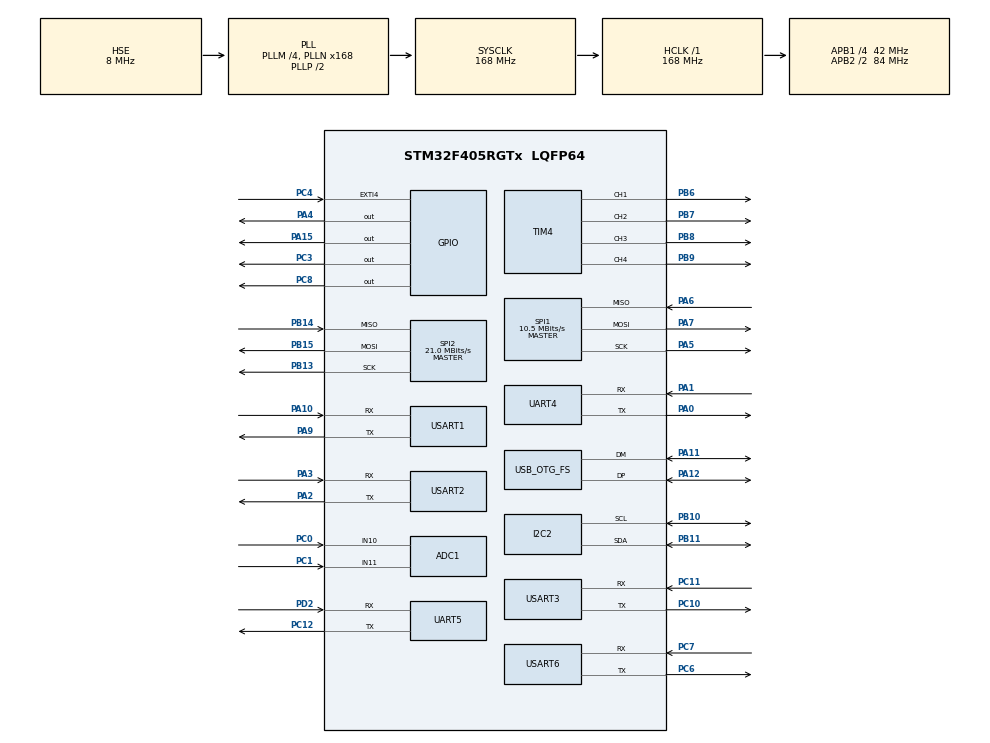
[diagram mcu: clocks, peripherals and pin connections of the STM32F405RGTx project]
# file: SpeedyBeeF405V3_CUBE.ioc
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ADC1.Channel-0\#ChannelRegularConversion=ADC_CHANNEL_10
ADC1.Channel-3\#ChannelRegularConversion=ADC_CHANNEL_11
ADC1.Channel-4\#ChannelRegularConversion=ADC_CHANNEL_TEMPSENSOR
ADC1.Channel-5\#ChannelRegularConversion=ADC_CHANNEL_VREFINT
ADC1.Channel-6\#ChannelRegularConversion=ADC_CHANNEL_VBAT
ADC1.ClockPrescaler=ADC_CLOCK_SYNC_PCLK_DIV8
ADC1.ContinuousConvMode=ENABLE
ADC1.DMAContinuousRequests=ENABLE
ADC1.ExternalTrigConv=ADC_SOFTWARE_START
ADC1.ExternalTrigConvEdge=ADC_EXTERNALTRIGCONVEDGE_NONE
ADC1.InjNumberOfConversion=0
ADC1.NbrOfConversion=5
ADC1.NbrOfConversionFlag=1
ADC1.Rank-0\#ChannelRegularConversion=1
ADC1.Rank-3\#ChannelRegularConversion=2
ADC1.Rank-4\#ChannelRegularConversion=3
ADC1.Rank-5\#ChannelRegularConversion=4
ADC1.Rank-6\#ChannelRegularConversion=5
ADC1.SamplingTime-0\#ChannelRegularConversion=ADC_SAMPLETIME_480CYCLES
ADC1.SamplingTime-3\#ChannelRegularConversion=ADC_SAMPLETIME_480CYCLES
ADC1.SamplingTime-4\#ChannelRegularConversion=ADC_SAMPLETIME_480CYCLES
ADC1.SamplingTime-5\#ChannelRegularConversion=ADC_SAMPLETIME_480CYCLES
ADC1.SamplingTime-6\#ChannelRegularConversion=ADC_SAMPLETIME_480CYCLES
ADC1.ScanConvMode=ENABLE
ADC1.master=1
Dma.ADC1.10.Direction=DMA_PERIPH_TO_MEMORY
Dma.ADC1.10.FIFOMode=DMA_FIFOMODE_DISABLE
Dma.ADC1.10.Instance=DMA2_Stream0
Dma.ADC1.10.MemDataAlignment=DMA_MDATAALIGN_HALFWORD
Dma.ADC1.10.MemInc=DMA_MINC_ENABLE
Dma.ADC1.10.Mode=DMA_CIRCULAR
Dma.ADC1.10.PeriphDataAlignment=DMA_PDATAALIGN_HALFWORD
Dma.ADC1.10.PeriphInc=DMA_PINC_DISABLE
Dma.ADC1.10.Priority=DMA_PRIORITY_HIGH
Dma.Request0=SPI2_TX
Dma.Request1=USART2_RX
Dma.Request10=ADC1
Dma.Request2=SPI1_RX
Dma.Request3=SPI1_TX
Dma.Request4=SPI2_RX
Dma.Request5=USART6_RX
Dma.Request6=USART3_RX
Dma.Request7=UART4_RX
Dma.Request8=UART5_RX
Dma.Request9=USART1_RX
Dma.SPI1_RX.2.Direction=DMA_PERIPH_TO_MEMORY
Dma.SPI1_RX.2.FIFOMode=DMA_FIFOMODE_DISABLE
Dma.SPI1_RX.2.Instance=DMA2_Stream2
Dma.SPI1_RX.2.MemDataAlignment=DMA_MDATAALIGN_BYTE
Dma.SPI1_RX.2.MemInc=DMA_MINC_ENABLE
Dma.SPI1_RX.2.Mode=DMA_NORMAL
Dma.SPI1_RX.2.PeriphDataAlignment=DMA_PDATAALIGN_BYTE
Dma.SPI1_RX.2.PeriphInc=DMA_PINC_DISABLE
Dma.SPI1_RX.2.Priority=DMA_PRIORITY_LOW
Dma.SPI1_TX.3.Direction=DMA_MEMORY_TO_PERIPH
Dma.SPI1_TX.3.FIFOMode=DMA_FIFOMODE_DISABLE
Dma.SPI1_TX.3.Instance=DMA2_Stream3
Dma.SPI1_TX.3.MemDataAlignment=DMA_MDATAALIGN_BYTE
Dma.SPI1_TX.3.MemInc=DMA_MINC_ENABLE
Dma.SPI1_TX.3.Mode=DMA_NORMAL
Dma.SPI1_TX.3.PeriphDataAlignment=DMA_PDATAALIGN_BYTE
Dma.SPI1_TX.3.PeriphInc=DMA_PINC_DISABLE
Dma.SPI1_TX.3.Priority=DMA_PRIORITY_LOW
Dma.SPI2_RX.4.Direction=DMA_PERIPH_TO_MEMORY
Dma.SPI2_RX.4.FIFOMode=DMA_FIFOMODE_DISABLE
Dma.SPI2_RX.4.Instance=DMA1_Stream3
Dma.SPI2_RX.4.MemDataAlignment=DMA_MDATAALIGN_BYTE
Dma.SPI2_RX.4.MemInc=DMA_MINC_ENABLE
Dma.SPI2_RX.4.Mode=DMA_NORMAL
Dma.SPI2_RX.4.PeriphDataAlignment=DMA_PDATAALIGN_BYTE
Dma.SPI2_RX.4.PeriphInc=DMA_PINC_DISABLE
Dma.SPI2_RX.4.Priority=DMA_PRIORITY_LOW
Dma.SPI2_TX.0.Direction=DMA_MEMORY_TO_PERIPH
Dma.SPI2_TX.0.FIFOMode=DMA_FIFOMODE_DISABLE
Dma.SPI2_TX.0.Instance=DMA1_Stream4
Dma.SPI2_TX.0.MemDataAlignment=DMA_MDATAALIGN_BYTE
Dma.SPI2_TX.0.MemInc=DMA_MINC_ENABLE
Dma.SPI2_TX.0.Mode=DMA_NORMAL
Dma.SPI2_TX.0.PeriphDataAlignment=DMA_PDATAALIGN_BYTE
Dma.SPI2_TX.0.PeriphInc=DMA_PINC_DISABLE
Dma.SPI2_TX.0.Priority=DMA_PRIORITY_LOW
Dma.UART4_RX.7.Direction=DMA_PERIPH_TO_MEMORY
Dma.UART4_RX.7.FIFOMode=DMA_FIFOMODE_DISABLE
Dma.UART4_RX.7.Instance=DMA1_Stream2
Dma.UART4_RX.7.MemDataAlignment=DMA_MDATAALIGN_BYTE
Dma.UART4_RX.7.MemInc=DMA_MINC_ENABLE
Dma.UART4_RX.7.Mode=DMA_CIRCULAR
Dma.UART4_RX.7.PeriphDataAlignment=DMA_PDATAALIGN_BYTE
Dma.UART4_RX.7.PeriphInc=DMA_PINC_DISABLE
Dma.UART4_RX.7.Priority=DMA_PRIORITY_LOW
Dma.UART5_RX.8.Direction=DMA_PERIPH_TO_MEMORY
Dma.UART5_RX.8.FIFOMode=DMA_FIFOMODE_DISABLE
Dma.UART5_RX.8.Instance=DMA1_Stream0
Dma.UART5_RX.8.MemDataAlignment=DMA_MDATAALIGN_BYTE
Dma.UART5_RX.8.MemInc=DMA_MINC_ENABLE
Dma.UART5_RX.8.Mode=DMA_CIRCULAR
Dma.UART5_RX.8.PeriphDataAlignment=DMA_PDATAALIGN_BYTE
Dma.UART5_RX.8.PeriphInc=DMA_PINC_DISABLE
Dma.UART5_RX.8.Priority=DMA_PRIORITY_LOW
Dma.USART1_RX.9.Direction=DMA_PERIPH_TO_MEMORY
Dma.USART1_RX.9.FIFOMode=DMA_FIFOMODE_DISABLE
Dma.USART1_RX.9.Instance=DMA2_Stream5
Dma.USART1_RX.9.MemDataAlignment=DMA_MDATAALIGN_BYTE
Dma.USART1_RX.9.MemInc=DMA_MINC_ENABLE
Dma.USART1_RX.9.Mode=DMA_CIRCULAR
Dma.USART1_RX.9.PeriphDataAlignment=DMA_PDATAALIGN_BYTE
Dma.USART1_RX.9.PeriphInc=DMA_PINC_DISABLE
Dma.USART1_RX.9.Priority=DMA_PRIORITY_LOW
Dma.USART2_RX.1.Direction=DMA_PERIPH_TO_MEMORY
Dma.USART2_RX.1.FIFOMode=DMA_FIFOMODE_DISABLE
Dma.USART2_RX.1.Instance=DMA1_Stream5
Dma.USART2_RX.1.MemDataAlignment=DMA_MDATAALIGN_BYTE
Dma.USART2_RX.1.MemInc=DMA_MINC_ENABLE
Dma.USART2_RX.1.Mode=DMA_CIRCULAR
Dma.USART2_RX.1.PeriphDataAlignment=DMA_PDATAALIGN_BYTE
Dma.USART2_RX.1.PeriphInc=DMA_PINC_DISABLE
Dma.USART2_RX.1.Priority=DMA_PRIORITY_LOW
Dma.USART3_RX.6.Direction=DMA_PERIPH_TO_MEMORY
Dma.USART3_RX.6.FIFOMode=DMA_FIFOMODE_DISABLE
Dma.USART3_RX.6.Instance=DMA1_Stream1
Dma.USART3_RX.6.MemDataAlignment=DMA_MDATAALIGN_BYTE
Dma.USART3_RX.6.MemInc=DMA_MINC_ENABLE
Dma.USART3_RX.6.Mode=DMA_CIRCULAR
Dma.USART3_RX.6.PeriphDataAlignment=DMA_PDATAALIGN_BYTE
Dma.USART3_RX.6.PeriphInc=DMA_PINC_DISABLE
Dma.USART3_RX.6.Priority=DMA_PRIORITY_LOW
Dma.USART6_RX.5.Direction=DMA_PERIPH_TO_MEMORY
Dma.USART6_RX.5.FIFOMode=DMA_FIFOMODE_DISABLE
Dma.USART6_RX.5.Instance=DMA2_Stream1
Dma.USART6_RX.5.MemDataAlignment=DMA_MDATAALIGN_BYTE
Dma.USART6_RX.5.MemInc=DMA_MINC_ENABLE
Dma.USART6_RX.5.Mode=DMA_CIRCULAR
Dma.USART6_RX.5.PeriphDataAlignment=DMA_PDATAALIGN_BYTE
Dma.USART6_RX.5.PeriphInc=DMA_PINC_DISABLE
Dma.USART6_RX.5.Priority=DMA_PRIORITY_LOW
I2C2.I2C_Mode=I2C_Fast
Mcu.Family=STM32F4
Mcu.Name=STM32F405RGTx
Mcu.Package=LQFP64
NVIC.ADC_IRQn=true\:0\:0\:false\:false\:true\:true\:true\:true
NVIC.DMA1_Stream0_IRQn=true\:0\:0\:false\:false\:true\:false\:true\:true
NVIC.DMA1_Stream1_IRQn=true\:0\:0\:false\:false\:true\:false\:true\:true
NVIC.DMA1_Stream2_IRQn=true\:0\:0\:false\:false\:true\:false\:true\:true
NVIC.DMA1_Stream3_IRQn=true\:0\:0\:false\:false\:true\:false\:true\:true
NVIC.DMA1_Stream4_IRQn=true\:0\:0\:false\:false\:true\:false\:true\:true
NVIC.DMA1_Stream5_IRQn=true\:0\:0\:false\:false\:true\:false\:true\:true
NVIC.DMA2_Stream0_IRQn=true\:0\:0\:false\:false\:true\:false\:true\:true
NVIC.DMA2_Stream1_IRQn=true\:0\:0\:false\:false\:true\:false\:true\:true
NVIC.DMA2_Stream2_IRQn=true\:0\:0\:false\:false\:true\:false\:true\:true
NVIC.DMA2_Stream3_IRQn=true\:0\:0\:false\:false\:true\:false\:true\:true
NVIC.DMA2_Stream5_IRQn=true\:0\:0\:false\:false\:true\:false\:true\:true
NVIC.EXTI4_IRQn=true\:0\:0\:false\:false\:true\:true\:true\:true
NVIC.I2C2_ER_IRQn=true\:0\:0\:false\:false\:true\:true\:true\:true
NVIC.I2C2_EV_IRQn=true\:0\:0\:false\:false\:true\:true\:true\:true
NVIC.OTG_FS_IRQn=true\:0\:0\:false\:false\:true\:false\:true\:true
NVIC.PriorityGroup=NVIC_PRIORITYGROUP_4
NVIC.SPI1_IRQn=true\:0\:0\:false\:false\:true\:true\:true\:true
NVIC.SPI2_IRQn=true\:0\:0\:false\:false\:true\:true\:true\:true
NVIC.UART4_IRQn=true\:0\:0\:false\:false\:true\:true\:true\:true
NVIC.UART5_IRQn=true\:0\:0\:false\:false\:true\:true\:true\:true
NVIC.USART1_IRQn=true\:0\:0\:false\:false\:true\:true\:true\:true
NVIC.USART2_IRQn=true\:0\:0\:false\:false\:true\:true\:true\:true
NVIC.USART3_IRQn=true\:0\:0\:false\:false\:true\:true\:true\:true
NVIC.USART6_IRQn=true\:0\:0\:false\:false\:true\:true\:true\:true
PA0-WKUP.Mode=Asynchronous
PA0-WKUP.Signal=UART4_TX
PA1.Mode=Asynchronous
PA1.Signal=UART4_RX
PA10.Mode=Asynchronous
PA10.Signal=USART1_RX
PA11.Mode=Device_Only
PA11.Signal=USB_OTG_FS_DM
PA12.Mode=Device_Only
PA12.Signal=USB_OTG_FS_DP
PA13.Mode=Serial_Wire
PA13.Signal=SYS_JTMS-SWDIO
PA14.Mode=Serial_Wire
PA14.Signal=SYS_JTCK-SWCLK
PA15.GPIO_Speed=GPIO_SPEED_FREQ_VERY_HIGH
PA15.PinState=GPIO_PIN_SET
PA15.Signal=GPIO_Output
PA2.Mode=Asynchronous
PA2.Signal=USART2_TX
PA3.Mode=Asynchronous
PA3.Signal=USART2_RX
PA4.GPIO_Speed=GPIO_SPEED_FREQ_VERY_HIGH
PA4.PinState=GPIO_PIN_SET
PA4.Signal=GPIO_Output
PA5.Mode=Full_Duplex_Master
PA5.Signal=SPI1_SCK
PA6.GPIO_PuPd=GPIO_NOPULL
PA6.Mode=Full_Duplex_Master
PA6.Signal=SPI1_MISO
PA7.Mode=Full_Duplex_Master
PA7.Signal=SPI1_MOSI
PA9.Mode=Asynchronous
PA9.Signal=USART1_TX
PB10.GPIO_Pu=GPIO_PULLUP
PB10.Mode=I2C
PB10.Signal=I2C2_SCL
PB11.GPIO_Pu=GPIO_PULLUP
PB11.Mode=I2C
PB11.Signal=I2C2_SDA
PB13.Mode=Full_Duplex_Master
PB13.Signal=SPI2_SCK
PB14.Mode=Full_Duplex_Master
PB14.Signal=SPI2_MISO
PB15.Mode=Full_Duplex_Master
PB15.Signal=SPI2_MOSI
PB6.Signal=S_TIM4_CH1
PB7.Signal=S_TIM4_CH2
PB8.Signal=S_TIM4_CH3
PB9.Signal=S_TIM4_CH4
PC0.Signal=ADCx_IN10
PC1.Signal=ADCx_IN11
PC10.Mode=Asynchronous
PC10.Signal=USART3_TX
PC11.Mode=Asynchronous
PC11.Signal=USART3_RX
PC12.Mode=Asynchronous
PC12.Signal=UART5_TX
PC3.Signal=GPIO_Output
PC4.Signal=GPXTI4
PC6.Mode=Asynchronous
PC6.Signal=USART6_TX
PC7.Mode=Asynchronous
PC7.Signal=USART6_RX
PC8.Signal=GPIO_Output
PD2.Mode=Asynchronous
PD2.Signal=UART5_RX
PH0-OSC_IN.Mode=HSE-External-Oscillator
PH0-OSC_IN.Signal=RCC_OSC_IN
PH1-OSC_OUT.Mode=HSE-External-Oscillator
PH1-OSC_OUT.Signal=RCC_OSC_OUT
ProjectManager.HeapSize=0x200
ProjectManager.StackSize=0x400
ProjectManager.TargetToolchain=STM32CubeIDE
RCC.48MHZClocksFreq_Value=48000000
RCC.AHBFreq_Value=168000000
RCC.APB1CLKDivider=RCC_HCLK_DIV4
RCC.APB1Freq_Value=42000000
RCC.APB1TimFreq_Value=84000000
RCC.APB2CLKDivider=RCC_HCLK_DIV2
RCC.APB2Freq_Value=84000000
RCC.APB2TimFreq_Value=168000000
RCC.CortexFreq_Value=168000000
RCC.HCLKFreq_Value=168000000
RCC.HSE_VALUE=8000000
RCC.HSI_VALUE=16000000
RCC.LSE_VALUE=32768
RCC.PLLM=4
RCC.PLLN=168
RCC.PLLQ=7
RCC.SYSCLKFreq_VALUE=168000000
RCC.SYSCLKSource=RCC_SYSCLKSOURCE_PLLCLK
RCC.VCOOutputFreq_Value=336000000
SH.ADCx_IN10.0=ADC1_IN10,IN10
SH.ADCx_IN11.0=ADC1_IN11,IN11
SH.S_TIM4_CH1.0=TIM4_CH1,PWM Generation1 CH1
SH.S_TIM4_CH2.0=TIM4_CH2,PWM Generation2 CH2
SH.S_TIM4_CH3.0=TIM4_CH3,PWM Generation3 CH3
SH.S_TIM4_CH4.0=TIM4_CH4,PWM Generation4 CH4
SPI1.BaudRatePrescaler=SPI_BAUDRATEPRESCALER_8
SPI1.CLKPhase=SPI_PHASE_2EDGE
SPI1.CLKPolarity=SPI_POLARITY_HIGH
SPI1.CalculateBaudRate=10.5 MBits/s
SPI1.Direction=SPI_DIRECTION_2LINES
SPI1.Mode=SPI_MODE_MASTER
SPI1.VirtualType=VM_MASTER
SPI2.CalculateBaudRate=21.0 MBits/s
SPI2.Direction=SPI_DIRECTION_2LINES
SPI2.Mode=SPI_MODE_MASTER
SPI2.VirtualType=VM_MASTER
TIM4.Channel-PWM\ Generation1\ CH1=TIM_CHANNEL_1
TIM4.Channel-PWM\ Generation2\ CH2=TIM_CHANNEL_2
TIM4.Channel-PWM\ Generation3\ CH3=TIM_CHANNEL_3
TIM4.Channel-PWM\ Generation4\ CH4=TIM_CHANNEL_4
UART4.VirtualMode=Asynchronous
UART5.VirtualMode=Asynchronous
USART1.VirtualMode=VM_ASYNC
USART2.VirtualMode=VM_ASYNC
USART3.VirtualMode=VM_ASYNC
USART6.VirtualMode=VM_ASYNC
USB_DEVICE.APP_RX_DATA_SIZE-CDC_FS=1024
USB_DEVICE.APP_TX_DATA_SIZE-CDC_FS=1024
USB_DEVICE.CLASS_NAME_FS=CDC
USB_DEVICE.VirtualMode-CDC_FS=Cdc
USB_DEVICE.VirtualModeFS=Cdc_FS
USB_OTG_FS.Sof_enable=ENABLE
USB_OTG_FS.VirtualMode=Device_Only
VP_ADC1_TempSens_Input.Mode=IN-TempSens
VP_ADC1_Vbat_Input.Mode=IN-Vbat
VP_ADC1_Vref_Input.Mode=IN-Vrefint
VP_FATFS_VS_Generic.Mode=User_defined
VP_RTC_VS_RTC_Activate.Mode=RTC_Enabled
VP_TIM4_VS_ClockSourceITR.Mode=TriggerSource_ITR0
VP_TIM4_VS_ControllerModeClock.Mode=Clock Mode
VP_USB_DEVICE_VS_USB_DEVICE_CDC_FS.Mode=CDC_FS
board=custom

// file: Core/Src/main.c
/* USER CODE BEGIN Header */
/**
  ******************************************************************************
  * @file           : main.c
  * @brief          : Main program body
  ******************************************************************************
  * @attention
  *
  * Copyright (c) 2023 STMicroelectronics.
  * All rights reserved.
  *
  * This software is licensed under terms that can be found in the LICENSE file
  * in the root directory of this software component.
  * If no LICENSE file comes with this software, it is provided AS-IS.
  *
  ******************************************************************************
  */
/* USER CODE END Header */
#include "main.h"
#include "adc.h"
#include "dma.h"
#include "fatfs.h"
#include "i2c.h"
#include "rtc.h"
#include "spi.h"
#include "tim.h"
#include "usart.h"
#include "usb_device.h"
#include "gpio.h"

/* USER CODE BEGIN PM */
#define BMI270_REG_CHIP_ID 0x00
extern SPI_HandleTypeDef hspi1;

/* USER CODE END PM */

void SystemClock_Config(void);

int main(void)
{

  /* MCU Configuration--------------------------------------------------------*/

  /* Reset of all peripherals, Initializes the Flash interface and the Systick. */
  HAL_Init();

  /* Configure the system clock */
  SystemClock_Config();

  /* Initialize all configured peripherals */
  MX_GPIO_Init();
  MX_DMA_Init();
  MX_USB_DEVICE_Init();
  MX_TIM4_Init();
  MX_I2C2_Init();
  MX_SPI1_Init();
  MX_SPI2_Init();
  MX_USART2_UART_Init();
  MX_USART6_UART_Init();
  MX_USART3_UART_Init();
  MX_UART4_Init();
  MX_UART5_Init();
  MX_USART1_UART_Init();
  MX_FATFS_Init();
  MX_ADC1_Init();
  MX_RTC_Init();
  /* USER CODE BEGIN 2 */
  HAL_GPIO_WritePin(GPIOA, GPIO_PIN_4, GPIO_PIN_SET);

  HAL_Delay(1000);

  uint8_t buffer[2] = {0, 0};

  HAL_StatusTypeDef status = 0;

  uint8_t addr = BMI270_REG_CHIP_ID | 0x80;

  HAL_GPIO_WritePin(GPIOA, GPIO_PIN_4, GPIO_PIN_RESET);

  HAL_SPI_Transmit(&hspi1, &addr, 1, 100);
  status = HAL_SPI_Receive(&hspi1, buffer, 2, 100);

  HAL_GPIO_WritePin(GPIOA, GPIO_PIN_4, GPIO_PIN_SET);

  if(status == 0)
  {
	  HAL_GPIO_WritePin(GPIOA, GPIO_PIN_4, GPIO_PIN_SET);
  }

  /* USER CODE END 2 */

  /* Infinite loop */
  while (1)
  {

  }
}

void SystemClock_Config(void)
{
  RCC_OscInitTypeDef RCC_OscInitStruct = {0};
  RCC_ClkInitTypeDef RCC_ClkInitStruct = {0};

  /** Configure the main internal regulator output voltage
  */
  __HAL_RCC_PWR_CLK_ENABLE();
  __HAL_PWR_VOLTAGESCALING_CONFIG(PWR_REGULATOR_VOLTAGE_SCALE1);

  /** Initializes the RCC Oscillators according to the specified parameters
  * in the RCC_OscInitTypeDef structure.
  */
  RCC_OscInitStruct.OscillatorType = RCC_OSCILLATORTYPE_LSI|RCC_OSCILLATORTYPE_HSE;
  RCC_OscInitStruct.HSEState = RCC_HSE_ON;
  RCC_OscInitStruct.LSIState = RCC_LSI_ON;
  RCC_OscInitStruct.PLL.PLLState = RCC_PLL_ON;
  RCC_OscInitStruct.PLL.PLLSource = RCC_PLLSOURCE_HSE;
  RCC_OscInitStruct.PLL.PLLM = 4;
  RCC_OscInitStruct.PLL.PLLN = 168;
  RCC_OscInitStruct.PLL.PLLP = RCC_PLLP_DIV2;
  RCC_OscInitStruct.PLL.PLLQ = 7;
  if (HAL_RCC_OscConfig(&RCC_OscInitStruct) != HAL_OK)
  {
    Error_Handler();
  }

  /** Initializes the CPU, AHB and APB buses clocks
  */
  RCC_ClkInitStruct.ClockType = RCC_CLOCKTYPE_HCLK|RCC_CLOCKTYPE_SYSCLK
                              |RCC_CLOCKTYPE_PCLK1|RCC_CLOCKTYPE_PCLK2;
  RCC_ClkInitStruct.SYSCLKSource = RCC_SYSCLKSOURCE_PLLCLK;
  RCC_ClkInitStruct.AHBCLKDivider = RCC_SYSCLK_DIV1;
  RCC_ClkInitStruct.APB1CLKDivider = RCC_HCLK_DIV4;
  RCC_ClkInitStruct.APB2CLKDivider = RCC_HCLK_DIV2;

  if (HAL_RCC_ClockConfig(&RCC_ClkInitStruct, FLASH_LATENCY_5) != HAL_OK)
  {
    Error_Handler();
  }
}

void Error_Handler(void)
{
  __disable_irq();
  while (1)
  {
  }
}
